# LargeDummyDevice register map
File version: 1.0
Registers are 32-bit, read-write, no defined reset value unless marked. A register's access mark holds for its fields unless they carry their own. Offsets are from the block's base; [hi:lo] are bit positions.

## PERIPHERAL_75
Base 0x4004A000
0x04 REG_1 — Register 1
  [30] FIELD_5, [28:25] FIELD_8, [27:23] FIELD_7, [24:22] FIELD_9, [21] FIELD_11, [21] FIELD_12, [16:13] FIELD_4, [14:11] FIELD_10, [12:8] FIELD_1, [7:6] FIELD_3, [8:6] FIELD_6, [7:3] FIELD_2
0x08 REG_2 — Register 2
  [30] FIELD_6, [27:24] FIELD_9, [25:23] FIELD_8, [19] FIELD_4, [21:17] FIELD_5, [16:12] FIELD_3, [12:9] FIELD_2, [9:7] FIELD_1, [6:5] FIELD_7
0x0C REG_3 — Register 3
  [34:31] FIELD_3, [23:22] FIELD_1, [15:11] FIELD_2, [5:4] FIELD_5, [4:0] FIELD_4
0x10 REG_4 — Register 4
  [34:31] FIELD_2, [33:30] FIELD_10, [30:28] FIELD_15, [27] FIELD_5, [28:27] FIELD_17, [27:23] FIELD_1, [20] FIELD_3, [21:20] FIELD_13, [19] FIELD_12, [17] FIELD_9, [18:17] FIELD_11, [15] FIELD_4, [7] FIELD_6, [7:4] FIELD_8, [6:2] FIELD_7, [4:1] FIELD_14, [5:1] FIELD_16
0x14 REG_5 — Register 5
  [29] FIELD_5, [30:28] FIELD_19, [32:28] FIELD_26, [31:27] FIELD_25, [27:26] FIELD_4, [28:26] FIELD_12, [22] FIELD_1, [23:21] FIELD_8, [23:20] FIELD_21, [22:19] FIELD_7, [22:19] FIELD_24, [22:18] FIELD_10, [17] FIELD_20, [17] FIELD_23, [19:16] FIELD_3, [19:15] FIELD_17, [15:13] FIELD_2, [15:12] FIELD_9, [15:12] FIELD_15, [12] FIELD_16, [13:11] FIELD_22, [9] FIELD_6, [11:9] FIELD_18, [8] FIELD_27, [6:3] FIELD_13, [3:1] FIELD_11, [2:1] FIELD_14
0x18 REG_6 — Register 6
  [34:31] FIELD_5, [32:31] FIELD_30, [30:28] FIELD_9, [29:28] FIELD_17, [29:27] FIELD_15, [28:26] FIELD_11, [28:26] FIELD_14, [27:26] FIELD_22, [26:24] FIELD_4, [28:24] FIELD_25, [26:23] FIELD_3, [26:22] FIELD_31, [24:20] FIELD_28, [22:18] FIELD_12, [20:17] FIELD_2, [20:17] FIELD_8, [17:16] FIELD_16, [18:15] FIELD_13, [15] FIELD_26, [16:13] FIELD_7, [17:13] FIELD_10, [12] FIELD_23, [11:10] FIELD_27, [9] FIELD_18, [12:8] FIELD_6, [8:7] FIELD_20, [8:5] FIELD_19, [5:4] FIELD_32, [6:3] FIELD_29, [3:2] FIELD_1, [4:2] FIELD_21, [1] FIELD_24
0x1C REG_7 — Register 7
  [33:30] FIELD_12, [34:30] FIELD_21, [31:29] FIELD_8, [27] FIELD_23, [20] FIELD_1, [23:20] FIELD_17, [20:19] FIELD_4, [18] FIELD_15, [17] FIELD_10, [16] FIELD_11, [16] FIELD_14, [17:15] FIELD_13, [16:13] FIELD_5, [12] FIELD_20, [12] FIELD_22, [7] FIELD_3, [6] FIELD_6, [9:6] FIELD_19, [5:3] FIELD_2, [5:3] FIELD_9, [4:3] FIELD_16, [7:3] FIELD_18, [3:2] FIELD_7
0x20 REG_8 — Register 8
  [16] FIELD_5, [18:14] FIELD_2, [16:13] FIELD_4, [6] FIELD_1, [5:1] FIELD_3
0x24 REG_9 — Register 9
  [34:31] FIELD_21, [31] FIELD_23, [31:29] FIELD_10, [32:29] FIELD_12, [32:28] FIELD_6, [29:27] FIELD_8, [26] FIELD_2, [23] FIELD_14, [26:22] FIELD_13, [24:20] FIELD_7, [22:18] FIELD_3, [21:18] FIELD_20, [16] FIELD_5, [17:14] FIELD_1, [17:14] FIELD_17, [16:13] FIELD_18, [15:13] FIELD_19, [14:13] FIELD_24, [13:11] FIELD_25, [12:8] FIELD_15, [6:5] FIELD_4, [8:5] FIELD_22, [5:4] FIELD_11, [4:2] FIELD_16, [1] FIELD_9
0x28 REG_10 — Register 10
  [35:31] FIELD_9, [34:30] FIELD_11, [32:29] FIELD_8, [27:26] FIELD_10, [28:24] FIELD_2, [28:24] FIELD_4, [24:23] FIELD_1, [27:23] FIELD_5, [18] FIELD_13, [13] FIELD_7, [12:9] FIELD_3, [4:3] FIELD_6, [7:3] FIELD_12
0x2C REG_11 — Register 11
  [21] FIELD_2, [7] FIELD_1, [9:7] FIELD_3
0x30 REG_12 — Register 12
  [31] FIELD_10, [30] FIELD_9, [31:29] FIELD_11, [28] FIELD_8, [19] FIELD_3, [18:17] FIELD_12, [19:16] FIELD_6, [15:12] FIELD_7, [14:11] FIELD_15, [12:9] FIELD_5, [12:8] FIELD_1, [7] FIELD_13, [8:6] FIELD_16, [5] FIELD_4, [8:5] FIELD_17, [4:3] FIELD_14, [2] FIELD_2, [4:0] FIELD_18
0x34 REG_13 — Register 13
  [34:31] FIELD_17, [31:27] FIELD_20, [26:25] FIELD_16, [27:23] FIELD_2, [23:22] FIELD_5, [19] FIELD_7, [15] FIELD_3, [14] FIELD_1, [18:14] FIELD_13, [16:14] FIELD_18, [13] FIELD_9, [13:10] FIELD_12, [9:6] FIELD_14, [9:5] FIELD_6, [6:4] FIELD_19, [4:3] FIELD_10, [6:3] FIELD_11, [3:2] FIELD_8, [2:0] FIELD_4, [3:0] FIELD_15
0x38 REG_14 — Register 14
  [20:16] FIELD_1
0x3C REG_15 — Register 15
  [31] FIELD_15, [29] FIELD_1, [32:29] FIELD_23, [29:28] FIELD_4, [29:27] FIELD_12, [29:27] FIELD_24, [27:26] FIELD_3, [27:24] FIELD_8, [26:22] FIELD_10, [19:18] FIELD_20, [19:15] FIELD_2, [17:14] FIELD_18, [16:13] FIELD_11, [15:13] FIELD_14, [15:12] FIELD_5, [13:10] FIELD_9, [12:10] FIELD_13, [11:8] FIELD_17, [10:7] FIELD_16, [8:4] FIELD_19, [3] FIELD_21, [2:0] FIELD_6, [1:0] FIELD_7, [3:0] FIELD_22
0x40 REG_16 — Register 16
  [32:30] FIELD_12, [32:29] FIELD_9, [29:28] FIELD_16, [30:28] FIELD_18, [27:26] FIELD_24, [29:25] FIELD_5, [27:25] FIELD_19, [26:25] FIELD_25, [27:24] FIELD_14, [24:21] FIELD_21, [20:18] FIELD_1, [20:18] FIELD_20, [18] FIELD_22, [20:17] FIELD_2, [15] FIELD_4, [18:15] FIELD_13, [16:15] FIELD_15, [14:13] FIELD_23, [16:13] FIELD_27, [14:12] FIELD_7, [14:11] FIELD_8, [9:6] FIELD_11, [8:6] FIELD_26, [7:5] FIELD_3, [5:4] FIELD_10, [5:4] FIELD_17, [3] FIELD_6
0x44 REG_17 — Register 17
  [30:29] FIELD_14, [30:28] FIELD_8, [30:27] FIELD_21, [28:27] FIELD_23, [30:26] FIELD_7, [29:26] FIELD_18, [28:25] FIELD_4, [27:23] FIELD_10, [26:22] FIELD_13, [24:20] FIELD_17, [19] FIELD_6, [21:19] FIELD_19, [16] FIELD_1, [17:13] FIELD_3, [15:13] FIELD_5, [13:11] FIELD_9, [14:11] FIELD_16, [13:10] FIELD_15, [13:9] FIELD_11, [8:7] FIELD_2, [6:5] FIELD_12, [8:5] FIELD_24, [5:4] FIELD_22, [5:3] FIELD_25, [3:1] FIELD_20
0x48 REG_18 — Register 18
  [33:31] FIELD_19, [33:30] FIELD_2, [29] FIELD_6, [30:29] FIELD_15, [30:29] FIELD_21, [30:28] FIELD_1, [29:28] FIELD_12, [31:28] FIELD_13, [31:27] FIELD_3, [29:27] FIELD_22, [27:25] FIELD_10, [29:25] FIELD_23, [19:18] FIELD_11, [18] FIELD_16, [17:15] FIELD_8, [17:15] FIELD_14, [15:13] FIELD_9, [11:7] FIELD_7, [7:6] FIELD_20, [5:4] FIELD_4, [4] FIELD_17, [4] FIELD_18, [3:2] FIELD_5
0x4C REG_19 — Register 19
  [24] FIELD_5, [23:21] FIELD_2, [24:21] FIELD_4, [21:20] FIELD_6, [11:9] FIELD_7, [8:7] FIELD_1, [2:0] FIELD_3
0x50 REG_20 — Register 20
  [26:22] FIELD_1, [23:20] FIELD_3, [20:18] FIELD_4, [19:18] FIELD_5, [15:11] FIELD_2
0x54 REG_21 — Register 21
  [35:31] FIELD_4, [34:30] FIELD_17, [32:29] FIELD_1, [30:29] FIELD_18, [30:27] FIELD_7, [30:27] FIELD_14, [28:27] FIELD_16, [24] FIELD_24, [25:24] FIELD_29, [22:21] FIELD_3, [21:20] FIELD_30, [21:19] FIELD_26, [21:17] FIELD_23, [17:16] FIELD_8, [18:15] FIELD_10, [19:15] FIELD_19, [18:14] FIELD_5, [15:14] FIELD_11, [13] FIELD_12, [17:13] FIELD_22, [16:12] FIELD_25, [13:10] FIELD_13, [11:10] FIELD_28, [12:9] FIELD_15, [12:8] FIELD_6, [10:8] FIELD_31, [7:6] FIELD_9, [9:6] FIELD_32, [3:2] FIELD_2, [6:2] FIELD_21, [1:0] FIELD_20, [3:0] FIELD_27
0x58 REG_22 — Register 22
  [32:31] FIELD_3, [33:31] FIELD_8, [27:26] FIELD_4, [28:25] FIELD_5, [26:22] FIELD_6, [25:22] FIELD_13, [24:21] FIELD_11, [21:17] FIELD_1, [16:15] FIELD_12, [14:12] FIELD_9, [4:3] FIELD_7, [5:2] FIELD_10, [3:0] FIELD_2
0x5C REG_23 — Register 23
  [29] FIELD_19, [30:27] FIELD_1, [26] FIELD_11, [25] FIELD_3, [27:25] FIELD_25, [27:23] FIELD_21, [23:22] FIELD_24, [25:21] FIELD_7, [25:21] FIELD_18, [24:21] FIELD_20, [21:19] FIELD_2, [23:19] FIELD_4, [17] FIELD_5, [21:17] FIELD_16, [18:15] FIELD_26, [17:14] FIELD_6, [14] FIELD_10, [16:14] FIELD_13, [13] FIELD_12, [10] FIELD_8, [9:7] FIELD_15, [4] FIELD_9, [3] FIELD_14, [3:2] FIELD_23, [3:0] FIELD_17, [0] FIELD_22
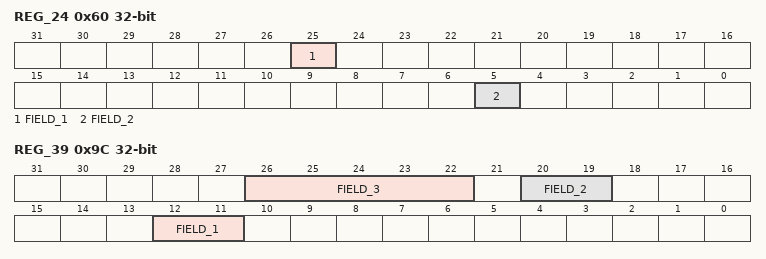
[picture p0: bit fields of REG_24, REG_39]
0x60 REG_24 — Register 24
  [25] FIELD_1, [5] FIELD_2
0x64 REG_25 — Register 25
  [33:31] FIELD_2, [19:15] FIELD_5, [17:14] FIELD_1, [14:10] FIELD_4, [9:8] FIELD_3
0x68 REG_26 — Register 26
  [33:30] FIELD_4, [28:26] FIELD_12, [29:26] FIELD_24, [29:25] FIELD_5, [29:25] FIELD_20, [28:24] FIELD_3, [27:24] FIELD_13, [26:23] FIELD_8, [27:23] FIELD_18, [24:23] FIELD_21, [24:23] FIELD_28, [25:23] FIELD_30, [22] FIELD_25, [20:18] FIELD_9, [20:16] FIELD_2, [19:15] FIELD_16, [18:14] FIELD_29, [15:13] FIELD_10, [14:10] FIELD_22, [11:10] FIELD_23, [12:9] FIELD_31, [8:7] FIELD_1, [7:5] FIELD_6, [7:5] FIELD_7, [5] FIELD_26, [7:4] FIELD_11, [6:2] FIELD_14, [2] FIELD_17, [0] FIELD_15, [3:0] FIELD_19, [4:0] FIELD_27
0x6C REG_27 — Register 27
  [35:31] FIELD_11, [29] FIELD_29, [30:28] FIELD_15, [31:27] FIELD_23, [29:26] FIELD_4, [27:26] FIELD_27, [28:25] FIELD_24, [26:24] FIELD_7, [27:24] FIELD_8, [27:24] FIELD_22, [26:23] FIELD_12, [26:23] FIELD_13, [22] FIELD_19, [24:21] FIELD_3, [23:20] FIELD_31, [19] FIELD_20, [20:18] FIELD_2, [19:17] FIELD_10, [21:17] FIELD_28, [19:16] FIELD_25, [14:13] FIELD_5, [16:12] FIELD_14, [14:11] FIELD_1, [11:8] FIELD_26, [10:6] FIELD_17, [9:6] FIELD_18, [9:6] FIELD_21, [9:5] FIELD_6, [7:5] FIELD_9, [6:2] FIELD_16, [2:1] FIELD_30
0x70 REG_28 — Register 28
  [34:30] FIELD_21, [30] FIELD_23, [30:28] FIELD_14, [30:26] FIELD_8, [30:26] FIELD_20, [26:25] FIELD_5, [28:24] FIELD_18, [24:21] FIELD_1, [20] FIELD_12, [19] FIELD_3, [18] FIELD_7, [18:17] FIELD_19, [15:11] FIELD_15, [10] FIELD_17, [11:9] FIELD_22, [11:7] FIELD_2, [9:7] FIELD_4, [7] FIELD_13, [8:6] FIELD_6, [9:5] FIELD_9, [6:5] FIELD_10, [2:1] FIELD_11, [1:0] FIELD_16
0x74 REG_29 — Register 29
  [32:30] FIELD_23, [30:29] FIELD_9, [31:29] FIELD_21, [30:28] FIELD_5, [27] FIELD_18, [27:25] FIELD_4, [27:25] FIELD_8, [24:23] FIELD_24, [23:20] FIELD_6, [17] FIELD_13, [20:17] FIELD_15, [17] FIELD_22, [16] FIELD_19, [17:15] FIELD_16, [17:15] FIELD_17, [16:14] FIELD_11, [13:11] FIELD_14, [11:8] FIELD_2, [12:8] FIELD_12, [8:4] FIELD_7, [5:3] FIELD_20, [6:2] FIELD_3, [1] FIELD_10, [0] FIELD_1
0x78 REG_30 — Register 30
  [32:28] FIELD_14, [27] FIELD_1, [31:27] FIELD_3, [31:27] FIELD_12, [28:25] FIELD_9, [27:24] FIELD_4, [23:22] FIELD_16, [23:20] FIELD_13, [19:16] FIELD_6, [18:16] FIELD_8, [18:15] FIELD_2, [18:14] FIELD_7, [15:11] FIELD_5, [14:10] FIELD_17, [12:10] FIELD_19, [7:5] FIELD_15, [6:4] FIELD_18, [2] FIELD_10, [2] FIELD_11
0x7C REG_31 — Register 31
  [28:27] FIELD_6, [31:27] FIELD_25, [26] FIELD_14, [25:23] FIELD_1, [27:23] FIELD_19, [23:21] FIELD_15, [19] FIELD_7, [21:19] FIELD_10, [18:17] FIELD_24, [17:14] FIELD_2, [15:13] FIELD_9, [14:12] FIELD_5, [11] FIELD_11, [15:11] FIELD_13, [13:10] FIELD_16, [10:9] FIELD_3, [10:8] FIELD_17, [9:7] FIELD_21, [10:7] FIELD_23, [9:6] FIELD_8, [7:6] FIELD_12, [5] FIELD_20, [5:3] FIELD_22, [3:2] FIELD_4, [3:0] FIELD_18
0x80 REG_32 — Register 32
  [31:30] FIELD_1
0x84 REG_33 — Register 33
  [33:30] FIELD_3, [24:23] FIELD_6, [12:10] FIELD_1, [7:6] FIELD_4, [7:5] FIELD_2, [4:1] FIELD_5
0x88 REG_34 — Register 34
  [22:18] FIELD_1
0x8C REG_35 — Register 35
  [28:24] FIELD_6, [11] FIELD_1, [11] FIELD_3, [11] FIELD_4, [13:10] FIELD_8, [12:8] FIELD_2, [7:6] FIELD_7, [7:3] FIELD_5
0x90 REG_36 — Register 36
  [32:31] FIELD_14, [34:30] FIELD_3, [33:29] FIELD_6, [31:28] FIELD_16, [30:27] FIELD_4, [31:27] FIELD_25, [26] FIELD_13, [27:25] FIELD_2, [27:25] FIELD_17, [24:23] FIELD_1, [25:23] FIELD_21, [22] FIELD_5, [22:19] FIELD_10, [20:19] FIELD_20, [17:16] FIELD_12, [19:16] FIELD_19, [19:15] FIELD_11, [14] FIELD_22, [18:14] FIELD_24, [15:13] FIELD_9, [11:10] FIELD_23, [9:7] FIELD_7, [6:5] FIELD_8, [6:4] FIELD_15, [4:3] FIELD_18
0x94 REG_37 — Register 37
  [32:30] FIELD_2, [31:27] FIELD_5, [24:22] FIELD_4, [14] FIELD_6, [13] FIELD_1, [11] FIELD_8, [12:9] FIELD_3, [3:1] FIELD_7
0x98 REG_38 — Register 38
  [33:31] FIELD_9, [28] FIELD_6, [29:27] FIELD_22, [30:27] FIELD_23, [26:23] FIELD_2, [26:23] FIELD_11, [22] FIELD_16, [20] FIELD_14, [23:19] FIELD_5, [21:18] FIELD_19, [19:17] FIELD_15, [20:17] FIELD_21, [15:13] FIELD_1, [11:10] FIELD_10, [11:10] FIELD_24, [13:9] FIELD_4, [9] FIELD_17, [11:9] FIELD_20, [10:6] FIELD_3, [7:6] FIELD_13, [8:5] FIELD_8, [6:3] FIELD_18, [4:2] FIELD_7, [2:0] FIELD_12
0x9C REG_39 — Register 39
  [26:22] FIELD_3, [20:19] FIELD_2, [12:11] FIELD_1
